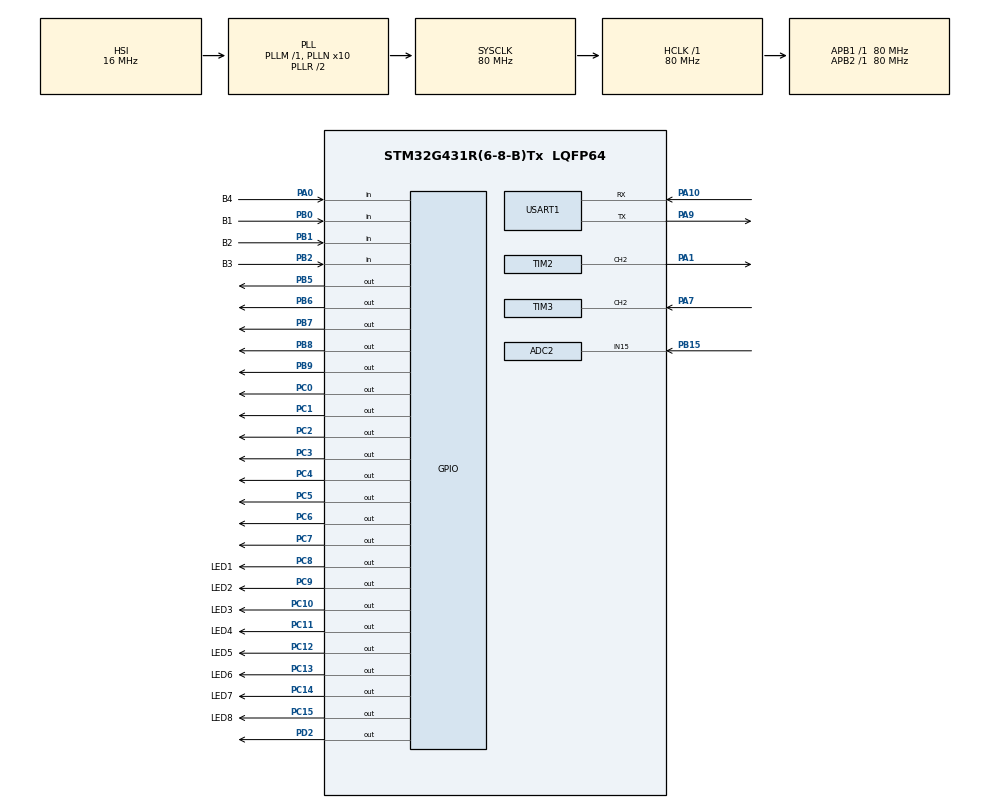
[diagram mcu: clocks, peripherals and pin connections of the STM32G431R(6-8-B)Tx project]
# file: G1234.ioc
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ADC2.Channel-0\#ChannelRegularConversion=ADC_CHANNEL_15
ADC2.NbrOfConversionFlag=1
ADC2.OffsetNumber-0\#ChannelRegularConversion=ADC_OFFSET_NONE
ADC2.Rank-0\#ChannelRegularConversion=1
ADC2.SamplingTime-0\#ChannelRegularConversion=ADC_SAMPLETIME_47CYCLES_5
Mcu.Family=STM32G4
Mcu.Name=STM32G431R(6-8-B)Tx
Mcu.Package=LQFP64
NVIC.PriorityGroup=NVIC_PRIORITYGROUP_4
NVIC.TIM3_IRQn=true\:0\:0\:false\:false\:true\:true\:true\:true
NVIC.TIM6_DAC_IRQn=true\:0\:0\:false\:false\:true\:true\:true\:true
PA0.GPIO_Label=B4
PA0.Signal=GPIO_Input
PA1.Signal=S_TIM2_CH2
PA10.Mode=Asynchronous
PA10.Signal=USART1_RX
PA13.Mode=Serial_Wire
PA13.Signal=SYS_JTMS-SWDIO
PA14.Mode=Serial_Wire
PA14.Signal=SYS_JTCK-SWCLK
PA7.Signal=S_TIM3_CH2
PA9.Mode=Asynchronous
PA9.Signal=USART1_TX
PB0.GPIO_Label=B1
PB0.Signal=GPIO_Input
PB1.GPIO_Label=B2
PB1.Signal=GPIO_Input
PB15.Mode=IN15-Single-Ended
PB15.Signal=ADC2_IN15
PB2.GPIO_Label=B3
PB2.Signal=GPIO_Input
PB5.Signal=GPIO_Output
PB6.GPIO_ModeDefaultOutputPP=GPIO_MODE_OUTPUT_OD
PB6.GPIO_PuPd=GPIO_NOPULL
PB6.Signal=GPIO_Output
PB7.GPIO_ModeDefaultOutputPP=GPIO_MODE_OUTPUT_OD
PB7.GPIO_PuPd=GPIO_NOPULL
PB7.Signal=GPIO_Output
PB8-BOOT0.Signal=GPIO_Output
PB9.Signal=GPIO_Output
PC0.Signal=GPIO_Output
PC1.Signal=GPIO_Output
PC10.GPIO_Label=LED3
PC10.Signal=GPIO_Output
PC11.GPIO_Label=LED4
PC11.Signal=GPIO_Output
PC12.GPIO_Label=LED5
PC12.Signal=GPIO_Output
PC13.GPIO_Label=LED6
PC13.Signal=GPIO_Output
PC14-OSC32_IN.GPIO_Label=LED7
PC14-OSC32_IN.Signal=GPIO_Output
PC15-OSC32_OUT.GPIO_Label=LED8
PC15-OSC32_OUT.Signal=GPIO_Output
PC2.Signal=GPIO_Output
PC3.Signal=GPIO_Output
PC4.Signal=GPIO_Output
PC5.Signal=GPIO_Output
PC6.Signal=GPIO_Output
PC7.Signal=GPIO_Output
PC8.GPIO_Label=LED1
PC8.Signal=GPIO_Output
PC9.GPIO_Label=LED2
PC9.Signal=GPIO_Output
PD2.Signal=GPIO_Output
PF0-OSC_IN.Mode=HSE-External-Oscillator
PF0-OSC_IN.Signal=RCC_OSC_IN
PF1-OSC_OUT.Mode=HSE-External-Oscillator
PF1-OSC_OUT.Signal=RCC_OSC_OUT
ProjectManager.HeapSize=0x200
ProjectManager.StackSize=0x400
ProjectManager.TargetToolchain=MDK-ARM V5.32
RCC.ADC12Freq_Value=80000000
RCC.AHBFreq_Value=80000000
RCC.APB1Freq_Value=80000000
RCC.APB1TimFreq_Value=80000000
RCC.APB2Freq_Value=80000000
RCC.APB2TimFreq_Value=80000000
RCC.CortexFreq_Value=80000000
RCC.EXTERNAL_CLOCK_VALUE=12288000
RCC.HCLKFreq_Value=80000000
RCC.HSE_VALUE=24000000
RCC.HSI48_VALUE=48000000
RCC.HSI_VALUE=16000000
RCC.LSE_VALUE=32768
RCC.PLLN=10
RCC.SYSCLKFreq_VALUE=80000000
RCC.SYSCLKSource=RCC_SYSCLKSOURCE_PLLCLK
RCC.USBFreq_Value=80000000
RCC.VCOOutputFreq_Value=160000000
SH.S_TIM2_CH2.0=TIM2_CH2,PWM Generation2 CH2
SH.S_TIM3_CH2.0=TIM3_CH2,Input_Capture2_from_TI2
TIM2.AutoReloadPreload=TIM_AUTORELOAD_PRELOAD_ENABLE
TIM2.Channel-PWM\ Generation2\ CH2=TIM_CHANNEL_2
TIM2.PeriodNoDither=1999
TIM2.Prescaler=9
TIM3.Channel-Input_Capture2_from_TI2=TIM_CHANNEL_2
TIM3.ICPolarity_CH2=TIM_INPUTCHANNELPOLARITY_RISING
TIM3.Prescaler=79
TIM6.PeriodNoDither=9999
TIM6.Prescaler=79
USART1.VirtualMode-Asynchronous=VM_ASYNC
VP_SYS_VS_DBSignals.Mode=DisableDeadBatterySignals
VP_TIM3_VS_ClockSourceINT.Mode=Internal
VP_TIM6_VS_ClockSourceINT.Mode=Enable_Timer
board=custom

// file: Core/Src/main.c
/* USER CODE BEGIN Header */
/**
 ******************************************************************************
 * @file           : main.c
 * @brief          : Main program body
 ******************************************************************************
 * @attention
 *
 * Copyright (c) 2024 STMicroelectronics.
 * All rights reserved.
 *
 * This software is licensed under terms that can be found in the LICENSE file
 * in the root directory of this software component.
 * If no LICENSE file comes with this software, it is provided AS-IS.
 *
 ******************************************************************************
 */
/* USER CODE END Header */
#include "main.h"

/* USER CODE BEGIN Includes */
#include "lcd_hal.h"
#include "user.h"
/* USER CODE END Includes */

ADC_HandleTypeDef hadc2;

TIM_HandleTypeDef htim2;
TIM_HandleTypeDef htim3;
TIM_HandleTypeDef htim6;

UART_HandleTypeDef huart1;

void SystemClock_Config(void);
static void MX_GPIO_Init(void);
static void MX_ADC2_Init(void);
static void MX_TIM2_Init(void);
static void MX_TIM3_Init(void);
static void MX_USART1_UART_Init(void);
static void MX_TIM6_Init(void);

int main(void)
{

  /* MCU Configuration--------------------------------------------------------*/

  /* Reset of all peripherals, Initializes the Flash interface and the Systick. */
  HAL_Init();

  /* Configure the system clock */
  SystemClock_Config();

  /* Initialize all configured peripherals */
  MX_GPIO_Init();
  MX_ADC2_Init();
  MX_TIM2_Init();
  MX_TIM3_Init();
  MX_USART1_UART_Init();
  MX_TIM6_Init();

  /* Infinite loop */
  /* USER CODE BEGIN WHILE */
    HAL_TIM_Base_Start_IT(&htim6);
    HAL_TIM_IC_Start_IT(&htim3, TIM_CHANNEL_2);
    LCD_Init();
    LCD_Clear(Black);
    LCD_SetBackColor(Black);
    LCD_SetTextColor(White);
    FreshPage();

    HAL_TIM_PWM_Start(&htim2, TIM_CHANNEL_2);
    while (1) {
        ScanKey();
    /* USER CODE END WHILE */

    }
}

void SystemClock_Config(void)
{
  RCC_OscInitTypeDef RCC_OscInitStruct = {0};
  RCC_ClkInitTypeDef RCC_ClkInitStruct = {0};

  /** Configure the main internal regulator output voltage
  */
  HAL_PWREx_ControlVoltageScaling(PWR_REGULATOR_VOLTAGE_SCALE1);

  /** Initializes the RCC Oscillators according to the specified parameters
  * in the RCC_OscInitTypeDef structure.
  */
  RCC_OscInitStruct.OscillatorType = RCC_OSCILLATORTYPE_HSI;
  RCC_OscInitStruct.HSIState = RCC_HSI_ON;
  RCC_OscInitStruct.HSICalibrationValue = RCC_HSICALIBRATION_DEFAULT;
  RCC_OscInitStruct.PLL.PLLState = RCC_PLL_ON;
  RCC_OscInitStruct.PLL.PLLSource = RCC_PLLSOURCE_HSI;
  RCC_OscInitStruct.PLL.PLLM = RCC_PLLM_DIV1;
  RCC_OscInitStruct.PLL.PLLN = 10;
  RCC_OscInitStruct.PLL.PLLP = RCC_PLLP_DIV2;
  RCC_OscInitStruct.PLL.PLLQ = RCC_PLLQ_DIV2;
  RCC_OscInitStruct.PLL.PLLR = RCC_PLLR_DIV2;
  if (HAL_RCC_OscConfig(&RCC_OscInitStruct) != HAL_OK)
  {
    Error_Handler();
  }

  /** Initializes the CPU, AHB and APB buses clocks
  */
  RCC_ClkInitStruct.ClockType = RCC_CLOCKTYPE_HCLK|RCC_CLOCKTYPE_SYSCLK
                              |RCC_CLOCKTYPE_PCLK1|RCC_CLOCKTYPE_PCLK2;
  RCC_ClkInitStruct.SYSCLKSource = RCC_SYSCLKSOURCE_PLLCLK;
  RCC_ClkInitStruct.AHBCLKDivider = RCC_SYSCLK_DIV1;
  RCC_ClkInitStruct.APB1CLKDivider = RCC_HCLK_DIV1;
  RCC_ClkInitStruct.APB2CLKDivider = RCC_HCLK_DIV1;

  if (HAL_RCC_ClockConfig(&RCC_ClkInitStruct, FLASH_LATENCY_2) != HAL_OK)
  {
    Error_Handler();
  }
}

static void MX_ADC2_Init(void)
{

  ADC_ChannelConfTypeDef sConfig = {0};

  /** Common config
  */
  hadc2.Instance = ADC2;
  hadc2.Init.ClockPrescaler = ADC_CLOCK_SYNC_PCLK_DIV2;
  hadc2.Init.Resolution = ADC_RESOLUTION_12B;
  hadc2.Init.DataAlign = ADC_DATAALIGN_RIGHT;
  hadc2.Init.GainCompensation = 0;
  hadc2.Init.ScanConvMode = ADC_SCAN_DISABLE;
  hadc2.Init.EOCSelection = ADC_EOC_SINGLE_CONV;
  hadc2.Init.LowPowerAutoWait = DISABLE;
  hadc2.Init.ContinuousConvMode = DISABLE;
  hadc2.Init.NbrOfConversion = 1;
  hadc2.Init.DiscontinuousConvMode = DISABLE;
  hadc2.Init.ExternalTrigConv = ADC_SOFTWARE_START;
  hadc2.Init.ExternalTrigConvEdge = ADC_EXTERNALTRIGCONVEDGE_NONE;
  hadc2.Init.DMAContinuousRequests = DISABLE;
  hadc2.Init.Overrun = ADC_OVR_DATA_PRESERVED;
  hadc2.Init.OversamplingMode = DISABLE;
  if (HAL_ADC_Init(&hadc2) != HAL_OK)
  {
    Error_Handler();
  }

  /** Configure Regular Channel
  */
  sConfig.Channel = ADC_CHANNEL_15;
  sConfig.Rank = ADC_REGULAR_RANK_1;
  sConfig.SamplingTime = ADC_SAMPLETIME_47CYCLES_5;
  sConfig.SingleDiff = ADC_SINGLE_ENDED;
  sConfig.OffsetNumber = ADC_OFFSET_NONE;
  sConfig.Offset = 0;
  if (HAL_ADC_ConfigChannel(&hadc2, &sConfig) != HAL_OK)
  {
    Error_Handler();
  }

}

static void MX_TIM2_Init(void)
{

  TIM_MasterConfigTypeDef sMasterConfig = {0};
  TIM_OC_InitTypeDef sConfigOC = {0};

  htim2.Instance = TIM2;
  htim2.Init.Prescaler = 9;
  htim2.Init.CounterMode = TIM_COUNTERMODE_UP;
  htim2.Init.Period = 1999;
  htim2.Init.ClockDivision = TIM_CLOCKDIVISION_DIV1;
  htim2.Init.AutoReloadPreload = TIM_AUTORELOAD_PRELOAD_ENABLE;
  if (HAL_TIM_PWM_Init(&htim2) != HAL_OK)
  {
    Error_Handler();
  }
  sMasterConfig.MasterOutputTrigger = TIM_TRGO_RESET;
  sMasterConfig.MasterSlaveMode = TIM_MASTERSLAVEMODE_DISABLE;
  if (HAL_TIMEx_MasterConfigSynchronization(&htim2, &sMasterConfig) != HAL_OK)
  {
    Error_Handler();
  }
  sConfigOC.OCMode = TIM_OCMODE_PWM1;
  sConfigOC.Pulse = 0;
  sConfigOC.OCPolarity = TIM_OCPOLARITY_HIGH;
  sConfigOC.OCFastMode = TIM_OCFAST_DISABLE;
  if (HAL_TIM_PWM_ConfigChannel(&htim2, &sConfigOC, TIM_CHANNEL_2) != HAL_OK)
  {
    Error_Handler();
  }
  HAL_TIM_MspPostInit(&htim2);

}

static void MX_TIM3_Init(void)
{

  TIM_ClockConfigTypeDef sClockSourceConfig = {0};
  TIM_MasterConfigTypeDef sMasterConfig = {0};
  TIM_IC_InitTypeDef sConfigIC = {0};

  htim3.Instance = TIM3;
  htim3.Init.Prescaler = 79;
  htim3.Init.CounterMode = TIM_COUNTERMODE_UP;
  htim3.Init.Period = 65535;
  htim3.Init.ClockDivision = TIM_CLOCKDIVISION_DIV1;
  htim3.Init.AutoReloadPreload = TIM_AUTORELOAD_PRELOAD_DISABLE;
  if (HAL_TIM_Base_Init(&htim3) != HAL_OK)
  {
    Error_Handler();
  }
  sClockSourceConfig.ClockSource = TIM_CLOCKSOURCE_INTERNAL;
  if (HAL_TIM_ConfigClockSource(&htim3, &sClockSourceConfig) != HAL_OK)
  {
    Error_Handler();
  }
  if (HAL_TIM_IC_Init(&htim3) != HAL_OK)
  {
    Error_Handler();
  }
  sMasterConfig.MasterOutputTrigger = TIM_TRGO_RESET;
  sMasterConfig.MasterSlaveMode = TIM_MASTERSLAVEMODE_DISABLE;
  if (HAL_TIMEx_MasterConfigSynchronization(&htim3, &sMasterConfig) != HAL_OK)
  {
    Error_Handler();
  }
  sConfigIC.ICPolarity = TIM_INPUTCHANNELPOLARITY_RISING;
  sConfigIC.ICSelection = TIM_ICSELECTION_DIRECTTI;
  sConfigIC.ICPrescaler = TIM_ICPSC_DIV1;
  sConfigIC.ICFilter = 0;
  if (HAL_TIM_IC_ConfigChannel(&htim3, &sConfigIC, TIM_CHANNEL_2) != HAL_OK)
  {
    Error_Handler();
  }

}

static void MX_TIM6_Init(void)
{

  TIM_MasterConfigTypeDef sMasterConfig = {0};

  htim6.Instance = TIM6;
  htim6.Init.Prescaler = 79;
  htim6.Init.CounterMode = TIM_COUNTERMODE_UP;
  htim6.Init.Period = 9999;
  htim6.Init.AutoReloadPreload = TIM_AUTORELOAD_PRELOAD_DISABLE;
  if (HAL_TIM_Base_Init(&htim6) != HAL_OK)
  {
    Error_Handler();
  }
  sMasterConfig.MasterOutputTrigger = TIM_TRGO_RESET;
  sMasterConfig.MasterSlaveMode = TIM_MASTERSLAVEMODE_DISABLE;
  if (HAL_TIMEx_MasterConfigSynchronization(&htim6, &sMasterConfig) != HAL_OK)
  {
    Error_Handler();
  }

}

static void MX_USART1_UART_Init(void)
{

  huart1.Instance = USART1;
  huart1.Init.BaudRate = 115200;
  huart1.Init.WordLength = UART_WORDLENGTH_8B;
  huart1.Init.StopBits = UART_STOPBITS_1;
  huart1.Init.Parity = UART_PARITY_NONE;
  huart1.Init.Mode = UART_MODE_TX_RX;
  huart1.Init.HwFlowCtl = UART_HWCONTROL_NONE;
  huart1.Init.OverSampling = UART_OVERSAMPLING_16;
  huart1.Init.OneBitSampling = UART_ONE_BIT_SAMPLE_DISABLE;
  huart1.Init.ClockPrescaler = UART_PRESCALER_DIV1;
  huart1.AdvancedInit.AdvFeatureInit = UART_ADVFEATURE_NO_INIT;
  if (HAL_UART_Init(&huart1) != HAL_OK)
  {
    Error_Handler();
  }
  if (HAL_UARTEx_SetTxFifoThreshold(&huart1, UART_TXFIFO_THRESHOLD_1_8) != HAL_OK)
  {
    Error_Handler();
  }
  if (HAL_UARTEx_SetRxFifoThreshold(&huart1, UART_RXFIFO_THRESHOLD_1_8) != HAL_OK)
  {
    Error_Handler();
  }
  if (HAL_UARTEx_DisableFifoMode(&huart1) != HAL_OK)
  {
    Error_Handler();
  }

}

static void MX_GPIO_Init(void)
{
  GPIO_InitTypeDef GPIO_InitStruct = {0};

  /* GPIO Ports Clock Enable */
  __HAL_RCC_GPIOC_CLK_ENABLE();
  __HAL_RCC_GPIOF_CLK_ENABLE();
  __HAL_RCC_GPIOA_CLK_ENABLE();
  __HAL_RCC_GPIOB_CLK_ENABLE();
  __HAL_RCC_GPIOD_CLK_ENABLE();

  /*Configure GPIO pin Output Level */
  HAL_GPIO_WritePin(GPIOC, LED6_Pin|LED7_Pin|LED8_Pin|GPIO_PIN_0
                          |GPIO_PIN_1|GPIO_PIN_2|GPIO_PIN_3|GPIO_PIN_4
                          |GPIO_PIN_5|GPIO_PIN_6|GPIO_PIN_7|LED1_Pin
                          |LED2_Pin|LED3_Pin|LED4_Pin|LED5_Pin, GPIO_PIN_RESET);

  /*Configure GPIO pin Output Level */
  HAL_GPIO_WritePin(GPIOD, GPIO_PIN_2, GPIO_PIN_RESET);

  /*Configure GPIO pin Output Level */
  HAL_GPIO_WritePin(GPIOB, GPIO_PIN_5|GPIO_PIN_6|GPIO_PIN_7|GPIO_PIN_8
                          |GPIO_PIN_9, GPIO_PIN_RESET);

  /*Configure GPIO pins : LED6_Pin LED7_Pin LED8_Pin PC0
                           PC1 PC2 PC3 PC4
                           PC5 PC6 PC7 LED1_Pin
                           LED2_Pin LED3_Pin LED4_Pin LED5_Pin */
  GPIO_InitStruct.Pin = LED6_Pin|LED7_Pin|LED8_Pin|GPIO_PIN_0
                          |GPIO_PIN_1|GPIO_PIN_2|GPIO_PIN_3|GPIO_PIN_4
                          |GPIO_PIN_5|GPIO_PIN_6|GPIO_PIN_7|LED1_Pin
                          |LED2_Pin|LED3_Pin|LED4_Pin|LED5_Pin;
  GPIO_InitStruct.Mode = GPIO_MODE_OUTPUT_PP;
  GPIO_InitStruct.Pull = GPIO_NOPULL;
  GPIO_InitStruct.Speed = GPIO_SPEED_FREQ_LOW;
  HAL_GPIO_Init(GPIOC, &GPIO_InitStruct);

  /*Configure GPIO pin : B4_Pin */
  GPIO_InitStruct.Pin = B4_Pin;
  GPIO_InitStruct.Mode = GPIO_MODE_INPUT;
  GPIO_InitStruct.Pull = GPIO_NOPULL;
  HAL_GPIO_Init(B4_GPIO_Port, &GPIO_InitStruct);

  /*Configure GPIO pins : B1_Pin B2_Pin B3_Pin */
  GPIO_InitStruct.Pin = B1_Pin|B2_Pin|B3_Pin;
  GPIO_InitStruct.Mode = GPIO_MODE_INPUT;
  GPIO_InitStruct.Pull = GPIO_NOPULL;
  HAL_GPIO_Init(GPIOB, &GPIO_InitStruct);

  /*Configure GPIO pin : PD2 */
  GPIO_InitStruct.Pin = GPIO_PIN_2;
  GPIO_InitStruct.Mode = GPIO_MODE_OUTPUT_PP;
  GPIO_InitStruct.Pull = GPIO_NOPULL;
  GPIO_InitStruct.Speed = GPIO_SPEED_FREQ_LOW;
  HAL_GPIO_Init(GPIOD, &GPIO_InitStruct);

  /*Configure GPIO pins : PB5 PB8 PB9 */
  GPIO_InitStruct.Pin = GPIO_PIN_5|GPIO_PIN_8|GPIO_PIN_9;
  GPIO_InitStruct.Mode = GPIO_MODE_OUTPUT_PP;
  GPIO_InitStruct.Pull = GPIO_NOPULL;
  GPIO_InitStruct.Speed = GPIO_SPEED_FREQ_LOW;
  HAL_GPIO_Init(GPIOB, &GPIO_InitStruct);

  /*Configure GPIO pins : PB6 PB7 */
  GPIO_InitStruct.Pin = GPIO_PIN_6|GPIO_PIN_7;
  GPIO_InitStruct.Mode = GPIO_MODE_OUTPUT_OD;
  GPIO_InitStruct.Pull = GPIO_NOPULL;
  GPIO_InitStruct.Speed = GPIO_SPEED_FREQ_LOW;
  HAL_GPIO_Init(GPIOB, &GPIO_InitStruct);

}

void Error_Handler(void)
{
    __disable_irq();
    while (1) {
    }
}
